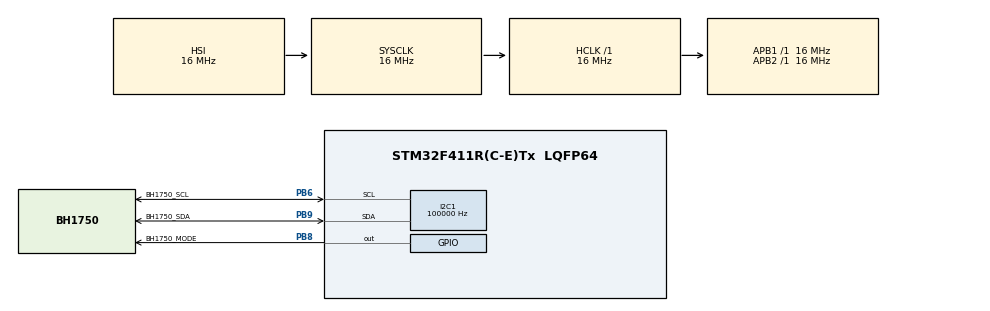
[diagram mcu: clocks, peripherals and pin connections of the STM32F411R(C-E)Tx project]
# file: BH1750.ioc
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I2C1.ClockSpeed=100000
I2C1.I2C_Mode=I2C_Standard
Mcu.Family=STM32F4
Mcu.Name=STM32F411R(C-E)Tx
Mcu.Package=LQFP64
NVIC.I2C1_ER_IRQn=true\:0\:0\:false\:false\:true\:true\:true\:true
NVIC.I2C1_EV_IRQn=true\:0\:0\:false\:false\:true\:true\:true\:true
NVIC.PriorityGroup=NVIC_PRIORITYGROUP_4
PA13.Mode=Serial_Wire
PA13.Signal=SYS_JTMS-SWDIO
PA14.Mode=Serial_Wire
PA14.Signal=SYS_JTCK-SWCLK
PB6.GPIO_Label=BH1750_SCL
PB6.GPIO_Pu=GPIO_PULLUP
PB6.Mode=I2C
PB6.Signal=I2C1_SCL
PB8.GPIO_Label=BH1750_MODE
PB8.Signal=GPIO_Output
PB9.GPIO_Label=BH1750_SDA
PB9.GPIO_Pu=GPIO_PULLUP
PB9.Mode=I2C
PB9.Signal=I2C1_SDA
ProjectManager.HeapSize=0x200
ProjectManager.StackSize=0x400
ProjectManager.TargetToolchain=STM32CubeIDE
RCC.AHBFreq_Value=16000000
RCC.APB1Freq_Value=16000000
RCC.APB2Freq_Value=16000000
RCC.CortexFreq_Value=16000000
RCC.HSE_VALUE=25000000
RCC.HSI_VALUE=16000000
RCC.LSE_VALUE=32768
RCC.SYSCLKFreq_VALUE=16000000
RCC.VCOOutputFreq_Value=192000000
board=custom

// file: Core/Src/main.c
/* USER CODE BEGIN Header */
/**
  ******************************************************************************
  * @file           : main.c
  * @brief          : Main program body
  ******************************************************************************
  * @attention
  *
  * Copyright (c) 2024 STMicroelectronics.
  * All rights reserved.
  *
  * This software is licensed under terms that can be found in the LICENSE file
  * in the root directory of this software component.
  * If no LICENSE file comes with this software, it is provided AS-IS.
  *
  ******************************************************************************
  */
/* USER CODE END Header */
#include "main.h"
#include "i2c.h"
#include "gpio.h"

/* USER CODE BEGIN Includes */
#include "BH1750.h"
/* USER CODE END Includes */

/* USER CODE BEGIN PV */
uint8_t buffer[2];
uint16_t value = 0;
/* USER CODE END PV */

void SystemClock_Config(void);

/* USER CODE BEGIN 0 */
//void HAL_I2C_MasterRxCpltCallback(I2C_HandleTypeDef *hi2c)
//{
//	if(hi2c->Instance == I2C1)
//	{
//		value = ((buffer[0] << 8) | buffer[1]);
//		value /= 1.2;
//
//
//	}
//	HAL_I2C_Master_Receive_IT(&hi2c1, ADDR_LOW_ADDRESS_READ, buffer, 2);
//}

/* USER CODE END 0 */

int main(void)
{

  /* MCU Configuration--------------------------------------------------------*/

  /* Reset of all peripherals, Initializes the Flash interface and the Systick. */
  HAL_Init();

  /* Configure the system clock */
  SystemClock_Config();

  /* Initialize all configured peripherals */
  MX_GPIO_Init();
  MX_I2C1_Init();
  /* USER CODE BEGIN 2 */
  buffer[0] = 0;
  buffer[1] = 0;
//	HAL_GPIO_WritePin(BH1750_MODE_GPIO_Port, BH1750_MODE_Pin, GPIO_PIN_RESET);		//ADDR = 'L' --> Continuous mode

	HAL_I2C_Master_Transmit(&hi2c1, ADDR_LOW_ADDRESS_WRITE, (uint8_t*)POWER_ON, 1, 10);
	HAL_I2C_Master_Transmit(&hi2c1, ADDR_LOW_ADDRESS_WRITE, (uint8_t*)RESET, 1, 10);
	HAL_I2C_Master_Transmit(&hi2c1, ADDR_LOW_ADDRESS_WRITE, (uint8_t*)CON_H_RES_MODE, 1, 10);

//	while(HAL_I2C_Master_Transmit(&hi2c1, ADDR_LOW_ADDRESS_WRITE, (uint8_t*)POWER_DOWN, 1, 120) != HAL_OK);
//	__HAL_I2C_CLEAR_FLAG(&hi2c1, I2C_FLAG_STOPF);
//	HAL_Delay(1000);
//
//	while(HAL_I2C_Master_Transmit(&hi2c1, ADDR_LOW_ADDRESS_WRITE, (uint8_t*)POWER_ON, 1, 120) != HAL_OK);
//	__HAL_I2C_CLEAR_FLAG(&hi2c1, I2C_FLAG_STOPF);
//	HAL_Delay(100);
//	while(HAL_I2C_Master_Transmit(&hi2c1, ADDR_LOW_ADDRESS_WRITE, (uint8_t*)RESET, 1, 120) != HAL_OK);
//	__HAL_I2C_CLEAR_FLAG(&hi2c1, I2C_FLAG_STOPF);
//	HAL_Delay(100);
//	while(HAL_I2C_Master_Transmit(&hi2c1, ADDR_LOW_ADDRESS_WRITE, (uint8_t*)CON_H_RES_MODE, 1, 120) != HAL_OK);
//	__HAL_I2C_CLEAR_FLAG(&hi2c1, I2C_FLAG_STOPF);
//	HAL_Delay(100);

//	HAL_I2C_Master_Receive_IT(&hi2c1, ADDR_LOW_ADDRESS_READ, buffer, 2);
  /* USER CODE END 2 */

  /* Infinite loop */
  /* USER CODE BEGIN WHILE */
  while (1)
  {
//	HAL_I2C_Master_Receive(&hi2c1, ADDR_LOW_ADDRESS_READ, buffer, 2, 1000);
//	HAL_Delay(100);
//
//	value = ((buffer[0] << 8) | buffer[1]);
//	value /= 1.2;
//	HAL_Delay(100);

	HAL_I2C_Master_Receive(&hi2c1, ADDR_LOW_ADDRESS_READ, buffer, 2, HAL_MAX_DELAY);

	value = ((buffer[0] << 8) | buffer[1]);
	value /= 1.2;
	HAL_Delay(150);
    /* USER CODE END WHILE */

  }
}

void SystemClock_Config(void)
{
  RCC_OscInitTypeDef RCC_OscInitStruct = {0};
  RCC_ClkInitTypeDef RCC_ClkInitStruct = {0};

  /** Configure the main internal regulator output voltage
  */
  __HAL_RCC_PWR_CLK_ENABLE();
  __HAL_PWR_VOLTAGESCALING_CONFIG(PWR_REGULATOR_VOLTAGE_SCALE1);

  /** Initializes the RCC Oscillators according to the specified parameters
  * in the RCC_OscInitTypeDef structure.
  */
  RCC_OscInitStruct.OscillatorType = RCC_OSCILLATORTYPE_HSI;
  RCC_OscInitStruct.HSIState = RCC_HSI_ON;
  RCC_OscInitStruct.HSICalibrationValue = RCC_HSICALIBRATION_DEFAULT;
  RCC_OscInitStruct.PLL.PLLState = RCC_PLL_NONE;
  if (HAL_RCC_OscConfig(&RCC_OscInitStruct) != HAL_OK)
  {
    Error_Handler();
  }

  /** Initializes the CPU, AHB and APB buses clocks
  */
  RCC_ClkInitStruct.ClockType = RCC_CLOCKTYPE_HCLK|RCC_CLOCKTYPE_SYSCLK
                              |RCC_CLOCKTYPE_PCLK1|RCC_CLOCKTYPE_PCLK2;
  RCC_ClkInitStruct.SYSCLKSource = RCC_SYSCLKSOURCE_HSI;
  RCC_ClkInitStruct.AHBCLKDivider = RCC_SYSCLK_DIV1;
  RCC_ClkInitStruct.APB1CLKDivider = RCC_HCLK_DIV1;
  RCC_ClkInitStruct.APB2CLKDivider = RCC_HCLK_DIV1;

  if (HAL_RCC_ClockConfig(&RCC_ClkInitStruct, FLASH_LATENCY_0) != HAL_OK)
  {
    Error_Handler();
  }
}

void Error_Handler(void)
{
  __disable_irq();
  while (1)
  {
  }
}
